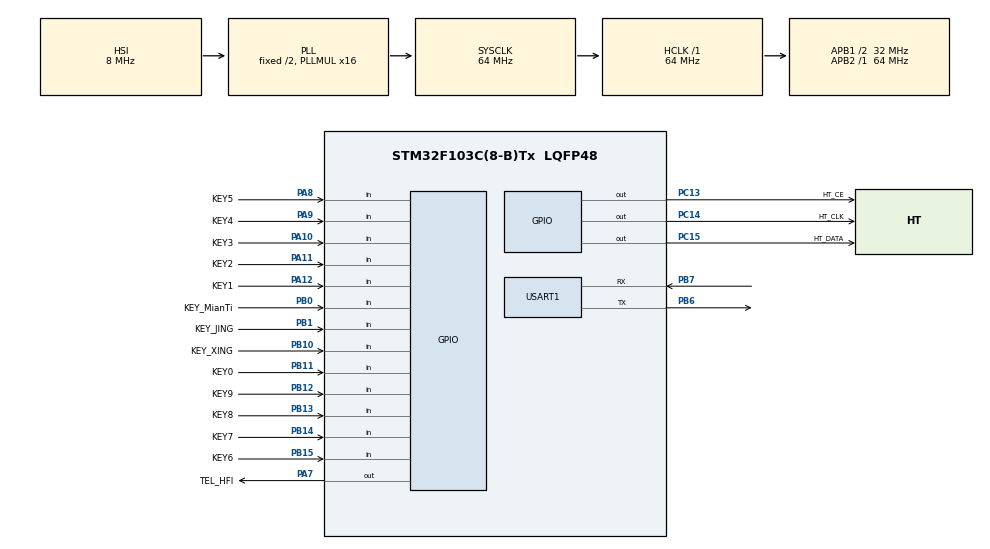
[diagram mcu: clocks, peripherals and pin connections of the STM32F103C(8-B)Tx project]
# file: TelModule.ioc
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Mcu.Family=STM32F1
Mcu.Name=STM32F103C(8-B)Tx
Mcu.Package=LQFP48
NVIC.PriorityGroup=NVIC_PRIORITYGROUP_4
NVIC.TIM3_IRQn=true\:0\:0\:false\:false\:true\:true
PA10.GPIO_Label=KEY3
PA10.GPIO_PuPd=GPIO_PULLUP
PA10.Signal=GPIO_Input
PA11.GPIO_Label=KEY2
PA11.GPIO_PuPd=GPIO_PULLUP
PA11.Signal=GPIO_Input
PA12.GPIO_Label=KEY1
PA12.GPIO_PuPd=GPIO_PULLUP
PA12.Signal=GPIO_Input
PA7.GPIO_Label=TEL_HFI
PA7.Signal=GPIO_Output
PA8.GPIO_Label=KEY5
PA8.GPIO_PuPd=GPIO_PULLUP
PA8.Signal=GPIO_Input
PA9.GPIO_Label=KEY4
PA9.GPIO_PuPd=GPIO_PULLUP
PA9.Signal=GPIO_Input
PB0.GPIO_Label=KEY_MianTi
PB0.GPIO_PuPd=GPIO_PULLUP
PB0.Signal=GPIO_Input
PB1.GPIO_Label=KEY_JING
PB1.GPIO_PuPd=GPIO_PULLUP
PB1.Signal=GPIO_Input
PB10.GPIO_Label=KEY_XING
PB10.GPIO_PuPd=GPIO_PULLUP
PB10.Signal=GPIO_Input
PB11.GPIO_Label=KEY0
PB11.GPIO_PuPd=GPIO_PULLUP
PB11.Signal=GPIO_Input
PB12.GPIO_Label=KEY9
PB12.GPIO_PuPd=GPIO_PULLUP
PB12.Signal=GPIO_Input
PB13.GPIO_Label=KEY8
PB13.GPIO_PuPd=GPIO_PULLUP
PB13.Signal=GPIO_Input
PB14.GPIO_Label=KEY7
PB14.GPIO_PuPd=GPIO_PULLUP
PB14.Signal=GPIO_Input
PB15.GPIO_Label=KEY6
PB15.GPIO_PuPd=GPIO_PULLUP
PB15.Signal=GPIO_Input
PB6.Mode=Asynchronous
PB6.Signal=USART1_TX
PB7.Mode=Asynchronous
PB7.Signal=USART1_RX
PC13-TAMPER-RTC.GPIO_Label=HT_CE
PC13-TAMPER-RTC.GPIO_ModeDefaultOutputPP=GPIO_MODE_OUTPUT_PP
PC13-TAMPER-RTC.GPIO_Speed=GPIO_SPEED_FREQ_HIGH
PC13-TAMPER-RTC.PinState=GPIO_PIN_SET
PC13-TAMPER-RTC.Signal=GPIO_Output
PC14-OSC32_IN.GPIO_Label=HT_CLK
PC14-OSC32_IN.GPIO_ModeDefaultOutputPP=GPIO_MODE_OUTPUT_PP
PC14-OSC32_IN.GPIO_Speed=GPIO_SPEED_FREQ_HIGH
PC14-OSC32_IN.PinState=GPIO_PIN_SET
PC14-OSC32_IN.Signal=GPIO_Output
PC15-OSC32_OUT.GPIO_Label=HT_DATA
PC15-OSC32_OUT.GPIO_ModeDefaultOutputPP=GPIO_MODE_OUTPUT_PP
PC15-OSC32_OUT.GPIO_Speed=GPIO_SPEED_FREQ_HIGH
PC15-OSC32_OUT.PinState=GPIO_PIN_SET
PC15-OSC32_OUT.Signal=GPIO_Output
ProjectManager.HeapSize=0x200
ProjectManager.StackSize=0x400
ProjectManager.TargetToolchain=TrueSTUDIO
RCC.AHBFreq_Value=64000000
RCC.APB1CLKDivider=RCC_HCLK_DIV2
RCC.APB1Freq_Value=32000000
RCC.APB1TimFreq_Value=64000000
RCC.APB2Freq_Value=64000000
RCC.APB2TimFreq_Value=64000000
RCC.HCLKFreq_Value=64000000
RCC.PLLMUL=RCC_PLL_MUL16
RCC.SYSCLKFreq_VALUE=64000000
RCC.SYSCLKSource=RCC_SYSCLKSOURCE_PLLCLK
RCC.USBFreq_Value=64000000
TIM3.Period=1000
TIM3.Prescaler=63
USART1.VirtualMode=VM_ASYNC
VP_SYS_VS_ND.Mode=No_Debug
VP_TIM3_VS_ClockSourceINT.Mode=Internal
board=TelModule

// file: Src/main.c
/**
  ******************************************************************************
  * File Name          : main.c
  * Description        : Main program body
  ******************************************************************************
  ** This notice applies to any and all portions of this file
  * that are not between comment pairs USER CODE BEGIN and
  * USER CODE END. Other portions of this file, whether
  * inserted by the user or by software development tools
  * are owned by their respective copyright owners.
  *
  * COPYRIGHT(c) 2017 STMicroelectronics
  *
  * Redistribution and use in source and binary forms, with or without modification,
  * are permitted provided that the following conditions are met:
  *   1. Redistributions of source code must retain the above copyright notice,
  *      this list of conditions and the following disclaimer.
  *   2. Redistributions in binary form must reproduce the above copyright notice,
  *      this list of conditions and the following disclaimer in the documentation
  *      and/or other materials provided with the distribution.
  *   3. Neither the name of STMicroelectronics nor the names of its contributors
  *      may be used to endorse or promote products derived from this software
  *      without specific prior written permission.
  *
  * THIS SOFTWARE IS PROVIDED BY THE COPYRIGHT HOLDERS AND CONTRIBUTORS "AS IS"
  * AND ANY EXPRESS OR IMPLIED WARRANTIES, INCLUDING, BUT NOT LIMITED TO, THE
  * IMPLIED WARRANTIES OF MERCHANTABILITY AND FITNESS FOR A PARTICULAR PURPOSE ARE
  * DISCLAIMED. IN NO EVENT SHALL THE COPYRIGHT HOLDER OR CONTRIBUTORS BE LIABLE
  * FOR ANY DIRECT, INDIRECT, INCIDENTAL, SPECIAL, EXEMPLARY, OR CONSEQUENTIAL
  * DAMAGES (INCLUDING, BUT NOT LIMITED TO, PROCUREMENT OF SUBSTITUTE GOODS OR
  * SERVICES; LOSS OF USE, DATA, OR PROFITS; OR BUSINESS INTERRUPTION) HOWEVER
  * CAUSED AND ON ANY THEORY OF LIABILITY, WHETHER IN CONTRACT, STRICT LIABILITY,
  * OR TORT (INCLUDING NEGLIGENCE OR OTHERWISE) ARISING IN ANY WAY OUT OF THE USE
  * OF THIS SOFTWARE, EVEN IF ADVISED OF THE POSSIBILITY OF SUCH DAMAGE.
  *
  ******************************************************************************
  */
#include "main.h"
#include "stm32f1xx_hal.h"
#include "tim.h"
#include "usart.h"
#include "gpio.h"

/* USER CODE BEGIN Includes */

#include "hal_key.h"

/* USER CODE END Includes */

/* USER CODE BEGIN PV */
/* Private variables ---------------------------------------------------------*/

/* USER CODE END PV */

void SystemClock_Config(void);

/* USER CODE BEGIN PFP */
/* Private function prototypes -----------------------------------------------*/

/* USER CODE END PFP */

int main(void)
{

  /* MCU Configuration----------------------------------------------------------*/

  /* Reset of all peripherals, Initializes the Flash interface and the Systick. */
  HAL_Init();

  /* Configure the system clock */
  SystemClock_Config();

  /* Initialize all configured peripherals */
  MX_GPIO_Init();
  MX_USART1_UART_Init();
  MX_TIM3_Init();

  /* USER CODE BEGIN 2 */
  keyInit();
  /* USER CODE END 2 */

  /* Infinite loop */
  while (1)
  {

  /* USER CODE BEGIN 3 */
	  keyScan();
  }
  /* USER CODE END 3 */

}

/** System Clock Configuration
*/
void SystemClock_Config(void)
{

  RCC_OscInitTypeDef RCC_OscInitStruct;
  RCC_ClkInitTypeDef RCC_ClkInitStruct;

    /**Initializes the CPU, AHB and APB busses clocks
    */
  RCC_OscInitStruct.OscillatorType = RCC_OSCILLATORTYPE_HSI;
  RCC_OscInitStruct.HSIState = RCC_HSI_ON;
  RCC_OscInitStruct.HSICalibrationValue = 16;
  RCC_OscInitStruct.PLL.PLLState = RCC_PLL_ON;
  RCC_OscInitStruct.PLL.PLLSource = RCC_PLLSOURCE_HSI_DIV2;
  RCC_OscInitStruct.PLL.PLLMUL = RCC_PLL_MUL16;
  if (HAL_RCC_OscConfig(&RCC_OscInitStruct) != HAL_OK)
  {
    _Error_Handler(__FILE__, __LINE__);
  }

    /**Initializes the CPU, AHB and APB busses clocks
    */
  RCC_ClkInitStruct.ClockType = RCC_CLOCKTYPE_HCLK|RCC_CLOCKTYPE_SYSCLK
                              |RCC_CLOCKTYPE_PCLK1|RCC_CLOCKTYPE_PCLK2;
  RCC_ClkInitStruct.SYSCLKSource = RCC_SYSCLKSOURCE_PLLCLK;
  RCC_ClkInitStruct.AHBCLKDivider = RCC_SYSCLK_DIV1;
  RCC_ClkInitStruct.APB1CLKDivider = RCC_HCLK_DIV2;
  RCC_ClkInitStruct.APB2CLKDivider = RCC_HCLK_DIV1;

  if (HAL_RCC_ClockConfig(&RCC_ClkInitStruct, FLASH_LATENCY_2) != HAL_OK)
  {
    _Error_Handler(__FILE__, __LINE__);
  }

    /**Configure the Systick interrupt time
    */
  HAL_SYSTICK_Config(HAL_RCC_GetHCLKFreq()/1000);

    /**Configure the Systick
    */
  HAL_SYSTICK_CLKSourceConfig(SYSTICK_CLKSOURCE_HCLK);

  /* SysTick_IRQn interrupt configuration */
  HAL_NVIC_SetPriority(SysTick_IRQn, 0, 0);
}

void _Error_Handler(char * file, int line)
{
  while(1)
  {
  }
}

/************************ (C) COPYRIGHT STMicroelectronics *****END OF FILE****/
